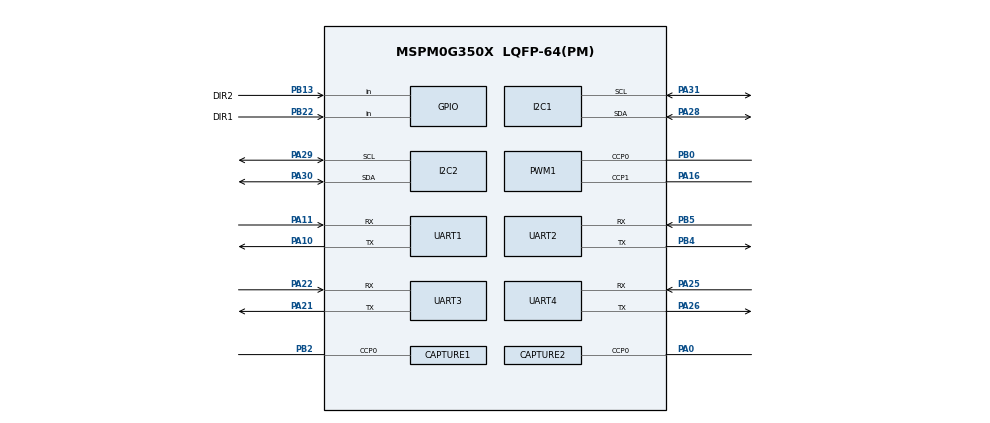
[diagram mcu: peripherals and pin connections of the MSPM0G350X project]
/**
 * @cliArgs --device "MSPM0G350X" --part "Default" --package "LQFP-64(PM)" --product "mspm0_sdk@2.10.00.04"
 * @versions {"tool":"1.26.2+4477"}
 */

/**
 * Import the modules used in this configuration.
 */
const CAPTURE  = scripting.addModule("/ti/driverlib/CAPTURE", {}, false);
const CAPTURE1 = CAPTURE.addInstance();
const CAPTURE2 = CAPTURE.addInstance();
const GPIO     = scripting.addModule("/ti/driverlib/GPIO", {}, false);
const GPIO1    = GPIO.addInstance();
const GPIO2    = GPIO.addInstance();
const GPIO3    = GPIO.addInstance();
const GPIO4    = GPIO.addInstance();
const GPIO5    = GPIO.addInstance();
const GPIO6    = GPIO.addInstance();
const GPIO7    = GPIO.addInstance();
const GPIO8    = GPIO.addInstance();
const GPIO9    = GPIO.addInstance();
const GPIO10   = GPIO.addInstance();
const I2C      = scripting.addModule("/ti/driverlib/I2C", {}, false);
const I2C1     = I2C.addInstance();
const I2C2     = I2C.addInstance();
const PWM      = scripting.addModule("/ti/driverlib/PWM", {}, false);
const PWM1     = PWM.addInstance();
const SYSCTL   = scripting.addModule("/ti/driverlib/SYSCTL");
const TIMER    = scripting.addModule("/ti/driverlib/TIMER", {}, false);
const TIMER1   = TIMER.addInstance();
const UART     = scripting.addModule("/ti/driverlib/UART", {}, false);
const UART1    = UART.addInstance();
const UART2    = UART.addInstance();
const UART3    = UART.addInstance();
const UART4    = UART.addInstance();

/**
 * Write custom configuration values to the imported modules.
 */
CAPTURE1.$name                              = "ENCODER2";
CAPTURE1.timerClkDiv                        = 8;
CAPTURE1.timerPeriod                        = "10ms";
CAPTURE1.timerStartTimer                    = true;
CAPTURE1.interrupts                         = ["CC0_DN"];
CAPTURE1.interruptPriority                  = "0";
CAPTURE1.peripheral.$assign                 = "TIMG6";
CAPTURE1.peripheral.ccp0Pin.$assign         = "PB2";
CAPTURE1.ccp0PinConfig.hideOutputInversion  = scripting.forceWrite(false);
CAPTURE1.ccp0PinConfig.onlyInternalResistor = scripting.forceWrite(false);
CAPTURE1.ccp0PinConfig.passedPeripheralType = scripting.forceWrite("Digital");
CAPTURE1.ccp0PinConfig.$name                = "ti_driverlib_gpio_GPIOPinGeneric23";

const Board = scripting.addModule("/ti/driverlib/Board", {}, false);

CAPTURE2.timerPeriod                        = "10ms";
CAPTURE2.timerClkDiv                        = 8;
CAPTURE2.timerStartTimer                    = true;
CAPTURE2.interrupts                         = ["CC0_DN"];
CAPTURE2.interruptPriority                  = "0";
CAPTURE2.$name                              = "ENCODER1";
CAPTURE2.peripheral.$assign                 = "TIMA0";
CAPTURE2.peripheral.ccp0Pin.$assign         = "PA0";
CAPTURE2.ccp0PinConfig.$name                = "ti_driverlib_gpio_GPIOPinGeneric14";
CAPTURE2.ccp0PinConfig.hideOutputInversion  = scripting.forceWrite(false);
CAPTURE2.ccp0PinConfig.onlyInternalResistor = scripting.forceWrite(false);
CAPTURE2.ccp0PinConfig.passedPeripheralType = scripting.forceWrite("Digital");

GPIO1.$name                          = "TB_DIR";
GPIO1.associatedPins.create(4);
GPIO1.associatedPins[0].assignedPort = "PORTA";
GPIO1.associatedPins[0].assignedPin  = "2";
GPIO1.associatedPins[0].$name        = "AIN1";
GPIO1.associatedPins[1].$name        = "AIN2";
GPIO1.associatedPins[1].assignedPort = "PORTB";
GPIO1.associatedPins[1].assignedPin  = "21";
GPIO1.associatedPins[2].$name        = "BIN1";
GPIO1.associatedPins[2].assignedPort = "PORTB";
GPIO1.associatedPins[2].assignedPin  = "19";
GPIO1.associatedPins[3].$name        = "BIN2";
GPIO1.associatedPins[3].assignedPort = "PORTB";
GPIO1.associatedPins[3].assignedPin  = "17";

GPIO2.$name                         = "BT_EN";
GPIO2.port                          = "PORTB";
GPIO2.associatedPins[0].$name       = "PIN_1";
GPIO2.associatedPins[0].assignedPin = "12";

GPIO3.$name                          = "I2C0";
GPIO3.associatedPins.create(2);
GPIO3.associatedPins[0].$name        = "SCL";
GPIO3.associatedPins[0].assignedPort = "PORTA";
GPIO3.associatedPins[0].assignedPin  = "13";
GPIO3.associatedPins[1].$name        = "SDA";
GPIO3.associatedPins[1].assignedPort = "PORTB";
GPIO3.associatedPins[1].assignedPin  = "26";

GPIO4.$name                          = "LED";
GPIO4.associatedPins.create(2);
GPIO4.associatedPins[0].assignedPort = "PORTA";
GPIO4.associatedPins[0].assignedPin  = "8";
GPIO4.associatedPins[0].$name        = "LED1";
GPIO4.associatedPins[1].$name        = "LED2";
GPIO4.associatedPins[1].assignedPort = "PORTA";
GPIO4.associatedPins[1].assignedPin  = "9";

GPIO5.$name                          = "KEY";
GPIO5.associatedPins.create(4);
GPIO5.associatedPins[0].$name        = "KEY1";
GPIO5.associatedPins[0].assignedPort = "PORTB";
GPIO5.associatedPins[0].assignedPin  = "15";
GPIO5.associatedPins[0].direction    = "INPUT";
GPIO5.associatedPins[1].$name        = "KEY2";
GPIO5.associatedPins[1].direction    = "INPUT";
GPIO5.associatedPins[1].assignedPort = "PORTB";
GPIO5.associatedPins[1].assignedPin  = "16";
GPIO5.associatedPins[2].$name        = "KEY3";
GPIO5.associatedPins[2].direction    = "INPUT";
GPIO5.associatedPins[2].assignedPort = "PORTB";
GPIO5.associatedPins[2].assignedPin  = "3";
GPIO5.associatedPins[3].$name        = "KEY4";
GPIO5.associatedPins[3].direction    = "INPUT";
GPIO5.associatedPins[3].assignedPort = "PORTB";
GPIO5.associatedPins[3].assignedPin  = "8";

GPIO6.$name                          = "BUZZER";
GPIO6.associatedPins[0].$name        = "PIN";
GPIO6.associatedPins[0].assignedPort = "PORTB";
GPIO6.associatedPins[0].assignedPin  = "6";

GPIO7.$name                          = "ENCODER_DIR";
GPIO7.associatedPins.create(2);
GPIO7.associatedPins[0].$name        = "DIR1";
GPIO7.associatedPins[0].assignedPort = "PORTB";
GPIO7.associatedPins[0].assignedPin  = "22";
GPIO7.associatedPins[0].polarity     = "RISE";
GPIO7.associatedPins[0].initialValue = "SET";
GPIO7.associatedPins[0].direction    = "INPUT";
GPIO7.associatedPins[0].pin.$assign  = "PB22";
GPIO7.associatedPins[1].$name        = "DIR2";
GPIO7.associatedPins[1].assignedPort = "PORTB";
GPIO7.associatedPins[1].assignedPin  = "13";
GPIO7.associatedPins[1].direction    = "INPUT";
GPIO7.associatedPins[1].polarity     = "RISE";
GPIO7.associatedPins[1].pin.$assign  = "PB13";

GPIO8.$name                          = "TRACK_AD";
GPIO8.associatedPins.create(3);
GPIO8.associatedPins[0].$name        = "AD0";
GPIO8.associatedPins[0].assignedPort = "PORTA";
GPIO8.associatedPins[0].assignedPin  = "14";
GPIO8.associatedPins[1].$name        = "AD1";
GPIO8.associatedPins[1].assignedPort = "PORTB";
GPIO8.associatedPins[1].assignedPin  = "20";
GPIO8.associatedPins[2].$name        = "AD2";
GPIO8.associatedPins[2].assignedPort = "PORTB";
GPIO8.associatedPins[2].assignedPin  = "25";

GPIO9.$name                          = "OLED_I2C";
GPIO9.associatedPins.create(2);
GPIO9.associatedPins[0].assignedPin  = "24";
GPIO9.associatedPins[0].assignedPort = "PORTB";
GPIO9.associatedPins[0].initialValue = "SET";
GPIO9.associatedPins[0].$name        = "OLED_SCL";
GPIO9.associatedPins[1].assignedPin  = "24";
GPIO9.associatedPins[1].assignedPort = "PORTA";
GPIO9.associatedPins[1].initialValue = "SET";
GPIO9.associatedPins[1].$name        = "OLED_SDA";

GPIO10.$name                          = "TRACK3";
GPIO10.associatedPins.create(5);
GPIO10.associatedPins[0].$name        = "OUT1";
GPIO10.associatedPins[0].direction    = "INPUT";
GPIO10.associatedPins[0].assignedPort = "PORTB";
GPIO10.associatedPins[0].assignedPin  = "18";
GPIO10.associatedPins[1].$name        = "OUT2";
GPIO10.associatedPins[1].assignedPort = "PORTB";
GPIO10.associatedPins[1].assignedPin  = "1";
GPIO10.associatedPins[1].direction    = "INPUT";
GPIO10.associatedPins[2].$name        = "OUT3";
GPIO10.associatedPins[2].assignedPort = "PORTB";
GPIO10.associatedPins[2].assignedPin  = "10";
GPIO10.associatedPins[2].direction    = "INPUT";
GPIO10.associatedPins[3].$name        = "OUT4";
GPIO10.associatedPins[3].assignedPort = "PORTB";
GPIO10.associatedPins[3].assignedPin  = "11";
GPIO10.associatedPins[3].direction    = "INPUT";
GPIO10.associatedPins[4].$name        = "OUT5";
GPIO10.associatedPins[4].assignedPort = "PORTB";
GPIO10.associatedPins[4].assignedPin  = "14";
GPIO10.associatedPins[4].direction    = "INPUT";

I2C1.basicEnableController             = true;
I2C1.$name                             = "ICM_I2C";
I2C1.peripheral.$assign                = "I2C0";
I2C1.peripheral.sdaPin.$assign         = "PA28";
I2C1.peripheral.sclPin.$assign         = "PA31";
I2C1.sdaPinConfig.hideOutputInversion  = scripting.forceWrite(false);
I2C1.sdaPinConfig.onlyInternalResistor = scripting.forceWrite(false);
I2C1.sdaPinConfig.passedPeripheralType = scripting.forceWrite("Digital");
I2C1.sdaPinConfig.$name                = "ti_driverlib_gpio_GPIOPinGeneric10";
I2C1.sclPinConfig.hideOutputInversion  = scripting.forceWrite(false);
I2C1.sclPinConfig.onlyInternalResistor = scripting.forceWrite(false);
I2C1.sclPinConfig.passedPeripheralType = scripting.forceWrite("Digital");
I2C1.sclPinConfig.$name                = "ti_driverlib_gpio_GPIOPinGeneric11";

I2C2.$name                             = "TRACK_I2C";
I2C2.peripheral.$assign                = "I2C1";
I2C2.peripheral.sdaPin.$assign         = "PA30";
I2C2.peripheral.sclPin.$assign         = "PA29";
I2C2.sdaPinConfig.hideOutputInversion  = scripting.forceWrite(false);
I2C2.sdaPinConfig.onlyInternalResistor = scripting.forceWrite(false);
I2C2.sdaPinConfig.passedPeripheralType = scripting.forceWrite("Digital");
I2C2.sdaPinConfig.$name                = "ti_driverlib_gpio_GPIOPinGeneric12";
I2C2.sclPinConfig.hideOutputInversion  = scripting.forceWrite(false);
I2C2.sclPinConfig.onlyInternalResistor = scripting.forceWrite(false);
I2C2.sclPinConfig.passedPeripheralType = scripting.forceWrite("Digital");
I2C2.sclPinConfig.$name                = "ti_driverlib_gpio_GPIOPinGeneric13";

PWM1.$name                              = "TB_PWM";
PWM1.timerStartTimer                    = true;
PWM1.peripheral.$assign                 = "TIMA1";
PWM1.peripheral.ccp0Pin.$assign         = "PB0";
PWM1.peripheral.ccp1Pin.$assign         = "PA16";
PWM1.PWM_CHANNEL_0.$name                = "ti_driverlib_pwm_PWMTimerCC0";
PWM1.PWM_CHANNEL_0.ccValue              = 0;
PWM1.PWM_CHANNEL_1.$name                = "ti_driverlib_pwm_PWMTimerCC1";
PWM1.PWM_CHANNEL_1.ccValue              = 0;
PWM1.ccp0PinConfig.direction            = scripting.forceWrite("OUTPUT");
PWM1.ccp0PinConfig.hideOutputInversion  = scripting.forceWrite(false);
PWM1.ccp0PinConfig.onlyInternalResistor = scripting.forceWrite(false);
PWM1.ccp0PinConfig.passedPeripheralType = scripting.forceWrite("Digital");
PWM1.ccp0PinConfig.$name                = "ti_driverlib_gpio_GPIOPinGeneric0";
PWM1.ccp1PinConfig.direction            = scripting.forceWrite("OUTPUT");
PWM1.ccp1PinConfig.hideOutputInversion  = scripting.forceWrite(false);
PWM1.ccp1PinConfig.onlyInternalResistor = scripting.forceWrite(false);
PWM1.ccp1PinConfig.passedPeripheralType = scripting.forceWrite("Digital");
PWM1.ccp1PinConfig.$name                = "ti_driverlib_gpio_GPIOPinGeneric1";

SYSCTL.forceDefaultClkConfig = true;
SYSCTL.MFPCLKEn              = true;

TIMER1.$name              = "TIMER_0";
TIMER1.timerClkDiv        = 8;
TIMER1.timerPeriod        = "10ms";
TIMER1.timerMode          = "PERIODIC";
TIMER1.interrupts         = ["ZERO"];
TIMER1.interruptPriority  = "1";
TIMER1.peripheral.$assign = "TIMG7";

UART1.targetBaudRate                   = 115200;
UART1.$name                            = "RESV1_UART";
UART1.peripheral.$assign               = "UART0";
UART1.peripheral.rxPin.$assign         = "PA11";
UART1.peripheral.txPin.$assign         = "PA10";
UART1.txPinConfig.direction            = scripting.forceWrite("OUTPUT");
UART1.txPinConfig.hideOutputInversion  = scripting.forceWrite(false);
UART1.txPinConfig.onlyInternalResistor = scripting.forceWrite(false);
UART1.txPinConfig.passedPeripheralType = scripting.forceWrite("Digital");
UART1.txPinConfig.$name                = "ti_driverlib_gpio_GPIOPinGeneric2";
UART1.rxPinConfig.hideOutputInversion  = scripting.forceWrite(false);
UART1.rxPinConfig.onlyInternalResistor = scripting.forceWrite(false);
UART1.rxPinConfig.passedPeripheralType = scripting.forceWrite("Digital");
UART1.rxPinConfig.$name                = "ti_driverlib_gpio_GPIOPinGeneric3";

UART2.$name                            = "STEP1_UART";
UART2.targetBaudRate                   = 115200;
UART2.peripheral.$assign               = "UART1";
UART2.peripheral.rxPin.$assign         = "PB5";
UART2.peripheral.txPin.$assign         = "PB4";
UART2.txPinConfig.direction            = scripting.forceWrite("OUTPUT");
UART2.txPinConfig.hideOutputInversion  = scripting.forceWrite(false);
UART2.txPinConfig.onlyInternalResistor = scripting.forceWrite(false);
UART2.txPinConfig.passedPeripheralType = scripting.forceWrite("Digital");
UART2.txPinConfig.$name                = "ti_driverlib_gpio_GPIOPinGeneric4";
UART2.rxPinConfig.hideOutputInversion  = scripting.forceWrite(false);
UART2.rxPinConfig.onlyInternalResistor = scripting.forceWrite(false);
UART2.rxPinConfig.passedPeripheralType = scripting.forceWrite("Digital");
UART2.rxPinConfig.$name                = "ti_driverlib_gpio_GPIOPinGeneric5";

UART3.targetBaudRate                   = 115200;
UART3.$name                            = "BT_UART";
UART3.peripheral.$assign               = "UART2";
UART3.peripheral.rxPin.$assign         = "PA22";
UART3.peripheral.txPin.$assign         = "PA21";
UART3.txPinConfig.direction            = scripting.forceWrite("OUTPUT");
UART3.txPinConfig.hideOutputInversion  = scripting.forceWrite(false);
UART3.txPinConfig.onlyInternalResistor = scripting.forceWrite(false);
UART3.txPinConfig.passedPeripheralType = scripting.forceWrite("Digital");
UART3.txPinConfig.$name                = "ti_driverlib_gpio_GPIOPinGeneric6";
UART3.rxPinConfig.hideOutputInversion  = scripting.forceWrite(false);
UART3.rxPinConfig.onlyInternalResistor = scripting.forceWrite(false);
UART3.rxPinConfig.passedPeripheralType = scripting.forceWrite("Digital");
UART3.rxPinConfig.$name                = "ti_driverlib_gpio_GPIOPinGeneric7";

UART4.$name                            = "RESV2_UART";
UART4.targetBaudRate                   = 115200;
UART4.peripheral.$assign               = "UART3";
UART4.peripheral.rxPin.$assign         = "PA25";
UART4.peripheral.txPin.$assign         = "PA26";
UART4.txPinConfig.direction            = scripting.forceWrite("OUTPUT");
UART4.txPinConfig.hideOutputInversion  = scripting.forceWrite(false);
UART4.txPinConfig.onlyInternalResistor = scripting.forceWrite(false);
UART4.txPinConfig.passedPeripheralType = scripting.forceWrite("Digital");
UART4.txPinConfig.$name                = "ti_driverlib_gpio_GPIOPinGeneric8";
UART4.rxPinConfig.hideOutputInversion  = scripting.forceWrite(false);
UART4.rxPinConfig.onlyInternalResistor = scripting.forceWrite(false);
UART4.rxPinConfig.passedPeripheralType = scripting.forceWrite("Digital");
UART4.rxPinConfig.$name                = "ti_driverlib_gpio_GPIOPinGeneric9";

/**
 * Pinmux solution for unlocked pins/peripherals. This ensures that minor changes to the automatic solver in a future
 * version of the tool will not impact the pinmux you originally saw.  These lines can be completely deleted in order to
 * re-solve from scratch.
 */
Board.peripheral.$suggestSolution             = "DEBUGSS";
Board.peripheral.swclkPin.$suggestSolution    = "PA20";
Board.peripheral.swdioPin.$suggestSolution    = "PA19";
GPIO1.associatedPins[0].pin.$suggestSolution  = "PA2";
GPIO1.associatedPins[1].pin.$suggestSolution  = "PB21";
GPIO1.associatedPins[2].pin.$suggestSolution  = "PB19";
GPIO1.associatedPins[3].pin.$suggestSolution  = "PB17";
GPIO2.associatedPins[0].pin.$suggestSolution  = "PB12";
GPIO3.associatedPins[0].pin.$suggestSolution  = "PA13";
GPIO3.associatedPins[1].pin.$suggestSolution  = "PB26";
GPIO4.associatedPins[0].pin.$suggestSolution  = "PA8";
GPIO4.associatedPins[1].pin.$suggestSolution  = "PA9";
GPIO5.associatedPins[0].pin.$suggestSolution  = "PB15";
GPIO5.associatedPins[1].pin.$suggestSolution  = "PB16";
GPIO5.associatedPins[2].pin.$suggestSolution  = "PB3";
GPIO5.associatedPins[3].pin.$suggestSolution  = "PB8";
GPIO6.associatedPins[0].pin.$suggestSolution  = "PB6";
GPIO8.associatedPins[0].pin.$suggestSolution  = "PA14";
GPIO8.associatedPins[1].pin.$suggestSolution  = "PB20";
GPIO8.associatedPins[2].pin.$suggestSolution  = "PB25";
GPIO9.associatedPins[0].pin.$suggestSolution  = "PB24";
GPIO9.associatedPins[1].pin.$suggestSolution  = "PA24";
GPIO10.associatedPins[0].pin.$suggestSolution = "PB18";
GPIO10.associatedPins[1].pin.$suggestSolution = "PB1";
GPIO10.associatedPins[2].pin.$suggestSolution = "PB10";
GPIO10.associatedPins[3].pin.$suggestSolution = "PB11";
GPIO10.associatedPins[4].pin.$suggestSolution = "PB14";
SYSCTL.peripheral.$suggestSolution            = "SYSCTL";
